# KM1M7CF06 register map
Vendor: Nuvoton Technology Corporation Japan; Series: KM1M7CF; File version: 1.0.3
CPU: CM7 r1p2, little endian, MPU, FPU, double-precision FPU, I-cache, D-cache, ITCM, DTCM, 4 interrupt priority bits
Registers are 16-bit, access per field, no defined reset value unless marked. A register's access mark holds for its fields unless they carry their own. Offsets are from the block's base; [hi:lo] are bit positions; 'fields as' and 'values as' point back to an identical list.

## DAC — D/A Converter
Base 0x40027000
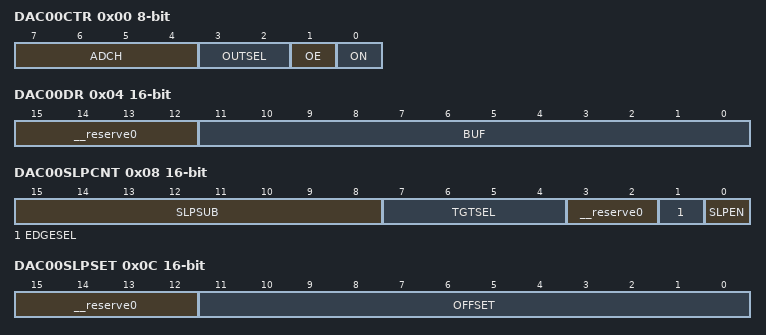
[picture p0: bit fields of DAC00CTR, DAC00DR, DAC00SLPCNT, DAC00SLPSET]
0x00 DAC00CTR 8-bit rw — DAC00 Control Register
  [7:4] ADCH — ADC conversion data buffer selection for DAC output
  [3:2] OUTSEL — DAOUT pin output data
  [1] OE — DAOUT pin output enable
  [0] ON — Operation control of D/A converter
0x04 DAC00DR — DAC00 Input Data Register
  [15:12] __reserve0 ro — "0" is always read out.
  [11:0] BUF rw — Set the input data that performs D/A conversion by DACn.
0x08 DAC00SLPCNT — DAC00 Slope Compensation Control Register
  [15:8] SLPSUB rw — Set slope compensation subtraction value.
  [7:4] TGTSEL rw — Slope compensation pin selection
  [3:2] __reserve0 ro — "0" is always read out.
  [1] EDGESEL rw — Slope compensation pin edge selection
  [0] SLPEN rw — D/An slope compensation enable
0x0C DAC00SLPSET — DAC00 Slope Compensation Setting Register
  [15:12] __reserve0 ro — "0" is always read out.
  [11:0] OFFSET rw — Set slope compensation subtraction start offset value.
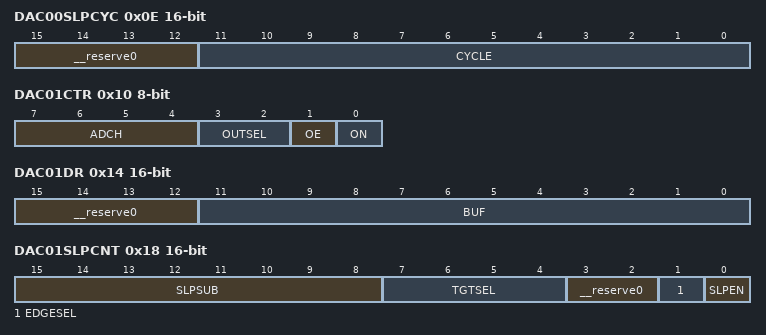
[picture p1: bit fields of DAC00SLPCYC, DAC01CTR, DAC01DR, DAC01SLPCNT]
0x0E DAC00SLPCYC — DAC00 Slope Compensation Cycle Register
  [15:12] __reserve0 ro — "0" is always read out.
  [11:0] CYCLE rw — Set slope compensation subtraction cycle.
0x10 DAC01CTR 8-bit rw — DAC01 Control Register
  fields as DAC00CTR
0x14 DAC01DR — DAC01 Input Data Register
  fields as DAC00DR
0x18 DAC01SLPCNT — DAC01 Slope Compensation Control Register
  fields as DAC00SLPCNT
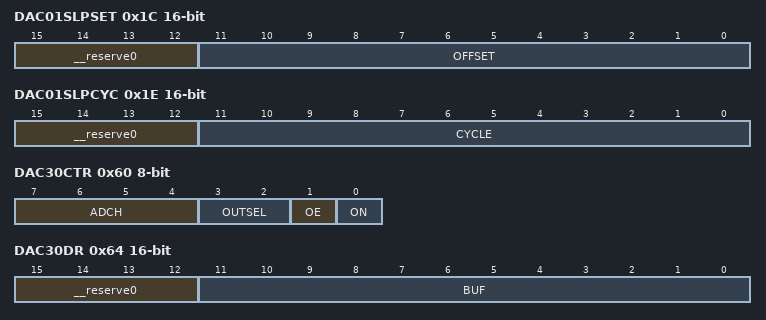
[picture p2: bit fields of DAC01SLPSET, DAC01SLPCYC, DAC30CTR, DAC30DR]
0x1C DAC01SLPSET — DAC01 Slope Compensation Setting Register
  fields as DAC00SLPSET
0x1E DAC01SLPCYC — DAC01 Slope Compensation Cycle Register
  fields as DAC00SLPCYC
0x60 DAC30CTR 8-bit rw — DAC30 Control Register
  fields as DAC00CTR
0x64 DAC30DR — DAC30 Input Data Register
  fields as DAC00DR
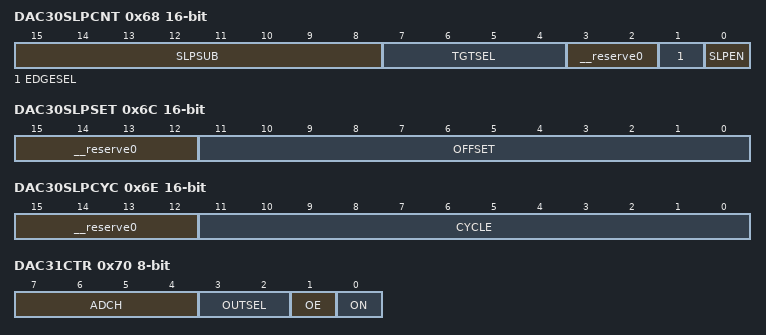
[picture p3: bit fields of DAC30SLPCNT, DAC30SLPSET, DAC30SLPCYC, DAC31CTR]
0x68 DAC30SLPCNT — DAC30 Slope Compensation Control Register
  fields as DAC00SLPCNT
0x6C DAC30SLPSET — DAC30 Slope Compensation Setting Register
  fields as DAC00SLPSET
0x6E DAC30SLPCYC — DAC30 Slope Compensation Cycle Register
  fields as DAC00SLPCYC
0x70 DAC31CTR 8-bit rw — DAC31 Control Register
  fields as DAC00CTR
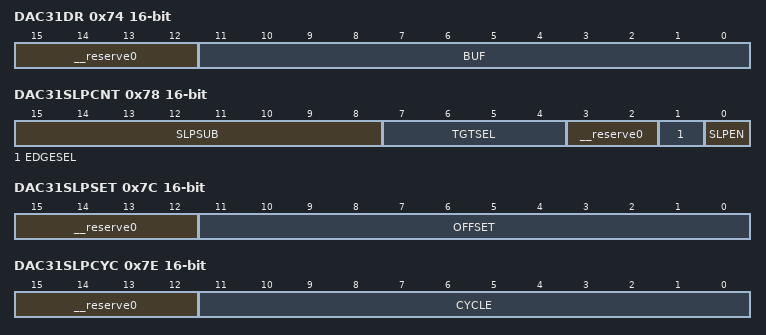
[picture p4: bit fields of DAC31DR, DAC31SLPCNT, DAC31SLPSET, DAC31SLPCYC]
0x74 DAC31DR — DAC31 Input Data Register
  fields as DAC00DR
0x78 DAC31SLPCNT — DAC31 Slope Compensation Control Register
  fields as DAC00SLPCNT
0x7C DAC31SLPSET — DAC31 Slope Compensation Setting Register
  fields as DAC00SLPSET
0x7E DAC31SLPCYC — DAC31 Slope Compensation Cycle Register
  fields as DAC00SLPCYC
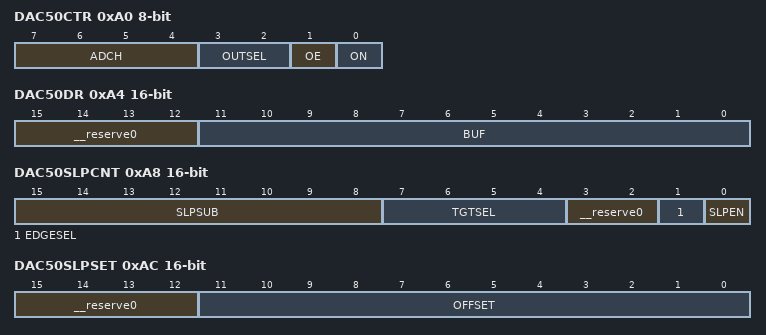
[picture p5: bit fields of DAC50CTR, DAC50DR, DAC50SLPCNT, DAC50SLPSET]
0xA0 DAC50CTR 8-bit rw — DAC50 Control Register
  fields as DAC00CTR
0xA4 DAC50DR — DAC50 Input Data Register
  fields as DAC00DR
0xA8 DAC50SLPCNT — DAC50 Slope Compensation Control Register
  fields as DAC00SLPCNT
0xAC DAC50SLPSET — DAC50 Slope Compensation Setting Register
  fields as DAC00SLPSET
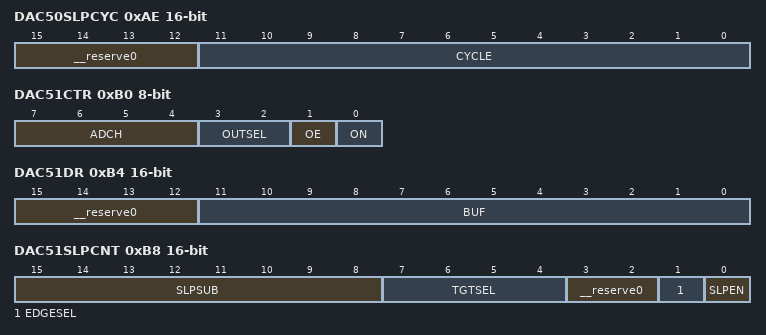
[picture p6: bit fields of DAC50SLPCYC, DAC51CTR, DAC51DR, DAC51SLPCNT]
0xAE DAC50SLPCYC — DAC50 Slope Compensation Cycle Register
  fields as DAC00SLPCYC
0xB0 DAC51CTR 8-bit rw — DAC51 Control Register
  fields as DAC00CTR
0xB4 DAC51DR — DAC51 Input Data Register
  fields as DAC00DR
0xB8 DAC51SLPCNT — DAC51 Slope Compensation Control Register
  fields as DAC00SLPCNT
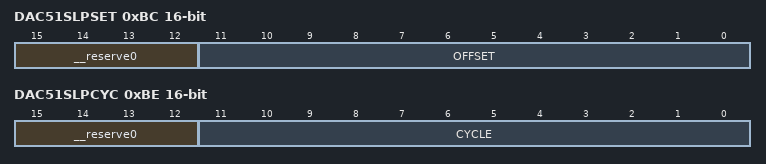
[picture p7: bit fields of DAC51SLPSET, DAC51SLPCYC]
0xBC DAC51SLPSET — DAC51 Slope Compensation Setting Register
  fields as DAC00SLPSET
0xBE DAC51SLPCYC — DAC51 Slope Compensation Cycle Register
  fields as DAC00SLPCYC

## LIN
Base 0x40050274
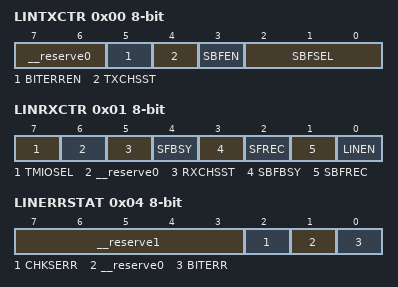
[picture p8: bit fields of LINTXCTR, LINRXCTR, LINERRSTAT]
0x00 LINTXCTR 8-bit — LIN Transmission Control Register
  [7:6] __reserve0 ro — "0" is always read out.
  [5] BITERREN rw — Bit error detection function selection
  [4] TXCHSST rw — Checksum operation for transmission
  [3] SBFEN rw — Synch Break field transmission trigger/monitor (*1)
  [2:0] SBFSEL rw — Synch Break field transmission width selection
0x01 LINRXCTR 8-bit — LIN Reception Control Register
  [7] TMIOSEL rw — Selection of clock source for Timer 12
  [6] __reserve0 rw — This bit must be set to "0".
  [5] RXCHSST rw — Checksum operation for reception
  [4] SFBSY ro — Synch field reception busy
  [3] SBFBSY ro — Synch Break field reception busy
  [2] SFREC rw — Enable Synch field reception
  [1] SBFREC rw — Enable Wake up signal and Synch Break field reception
  [0] LINEN rw — Enable LIN communication
0x04 LINERRSTAT 8-bit ro — LIN Error Status Register
  [7:3] __reserve1 — "0" is always read out.
  [2] CHKSERR — Checksum error detection (*1) (*2)
  [1] __reserve0 — "0" is always read out.
  [0] BITERR — Bit error detection (*3)
0x08 LINTXCHKS 8-bit ro — LIN Transmission Checksum Register
  [7:0] TXCHKS — Checksum value for the transmission data is read out.
0x09 LINRXCHKS 8-bit ro — LIN Reception Checksum Register
  [7:0] RXCHKS — Checksum value for the reception data is read out.

## CMP — Comparator
Base 0x40054000
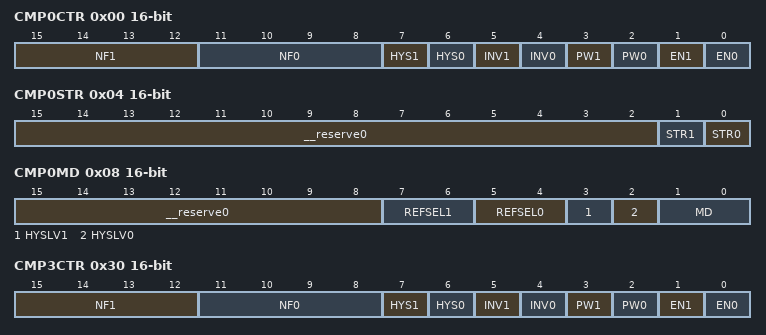
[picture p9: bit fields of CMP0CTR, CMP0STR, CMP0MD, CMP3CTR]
0x00 CMP0CTR rw — Comparator 0 Control Register
  [15:12] NF1 — Selection of comparator n1 output noise filter
  [11:8] NF0 — Selection of comparator n0 output noise filter
  [7] HYS1 — CMPn1 hysteresis setting
  [6] HYS0 — CMPn0 hysteresis setting
  [5] INV1 — Selection of CMPn1 comparator detection polarity
  [4] INV0 — Selection of CMPn0 comparator detection polarity
  [3] PW1 — Operation of the CMPn1 comparator
  [2] PW0 — Operation of the CMPn0 comparator
  [1] EN1 — Start of the comparator n1 comparison
  [0] EN0 — Start of the comparator n0 comparison
0x04 CMP0STR ro — Comparator 0 Status Register
  [15:2] __reserve0 — "0" is always read out.
  [1] STR1 — Detection state of CMPn1
  [0] STR0 — Detection state of CMPn0
0x08 CMP0MD — Comparator 0 Mode Register
  [15:8] __reserve0 ro — "0" is always read out.
  [7:6] REFSEL1 rw — CMPn1reference voltage
  [5:4] REFSEL0 rw — CMPn0 refernce voltage
  [3] HYSLV1 rw — CMPn1 hysteresis width (*)
  [2] HYSLV0 rw — CMPn0 hysteresis width (*)
  [1:0] MD rw — CMPn operating mode
0x30 CMP3CTR rw — Comparator 3 Control Register
  fields as CMP0CTR
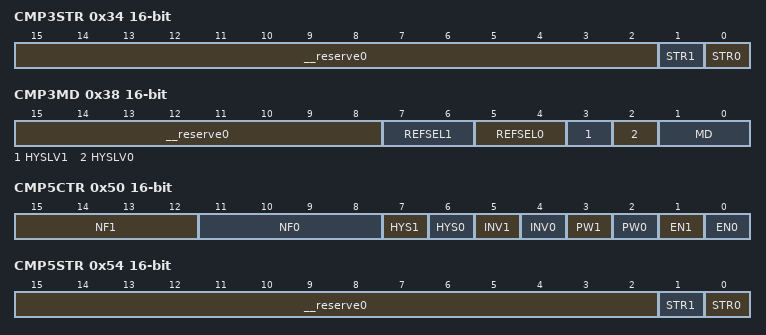
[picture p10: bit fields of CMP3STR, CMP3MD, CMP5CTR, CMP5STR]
0x34 CMP3STR ro — Comparator 3 Status Register
  fields as CMP0STR
0x38 CMP3MD — Comparator 3 Mode Register
  fields as CMP0MD
0x50 CMP5CTR rw — Comparator 5 Control Register
  fields as CMP0CTR
0x54 CMP5STR ro — Comparator 5 Status Register
  fields as CMP0STR
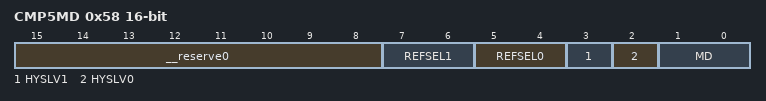
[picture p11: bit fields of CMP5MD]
0x58 CMP5MD — Comparator 5 Mode Register
  fields as CMP0MD

## PWRDET — Power Supply Voltage Detection
Base 0x40056000
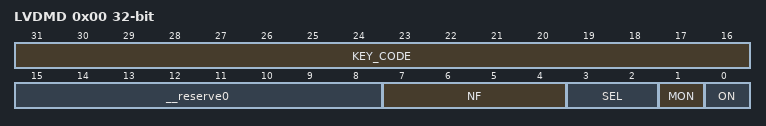
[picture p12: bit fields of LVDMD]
0x00 LVDMD 32-bit — Power Supply Voltage Detection Control Register
  [31:16] KEY_CODE wo — Register Key
  [15:8] __reserve0 ro — "0" is always read out.
  [7:4] NF rw — Selection of power supply voltage detection signal noise filter
  [3:2] SEL rw — Power supply voltage detection level selection (*)
  [1] MON ro — Power supply voltage monitor bit
  [0] ON rw — Power supply voltage detection function control
